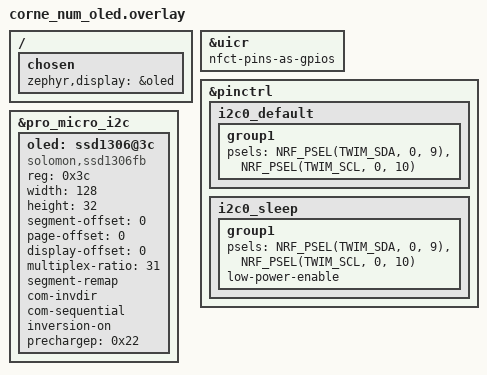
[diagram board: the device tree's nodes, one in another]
/* 0.91in 128x32 SSD1306 on P0.09 (SDA) / P0.10 (SCL). These are the NFC pins, so free them as GPIO. */
&uicr {
    nfct-pins-as-gpios;
};

&pinctrl {
    i2c0_default: i2c0_default {
        group1 {
            psels = <NRF_PSEL(TWIM_SDA, 0, 9)>,
                    <NRF_PSEL(TWIM_SCL, 0, 10)>;
        };
    };

    i2c0_sleep: i2c0_sleep {
        group1 {
            psels = <NRF_PSEL(TWIM_SDA, 0, 9)>,
                    <NRF_PSEL(TWIM_SCL, 0, 10)>;
            low-power-enable;
        };
    };
};

&pro_micro_i2c {
    status = "okay";

    oled: ssd1306@3c {
        compatible = "solomon,ssd1306fb";
        reg = <0x3c>;
        width = <128>;
        height = <32>;
        segment-offset = <0>;
        page-offset = <0>;
        display-offset = <0>;
        multiplex-ratio = <31>;
        segment-remap;
        com-invdir;
        com-sequential;
        inversion-on;
        prechargep = <0x22>;
    };
};

/ {
    chosen {
        zephyr,display = &oled;
    };
};
